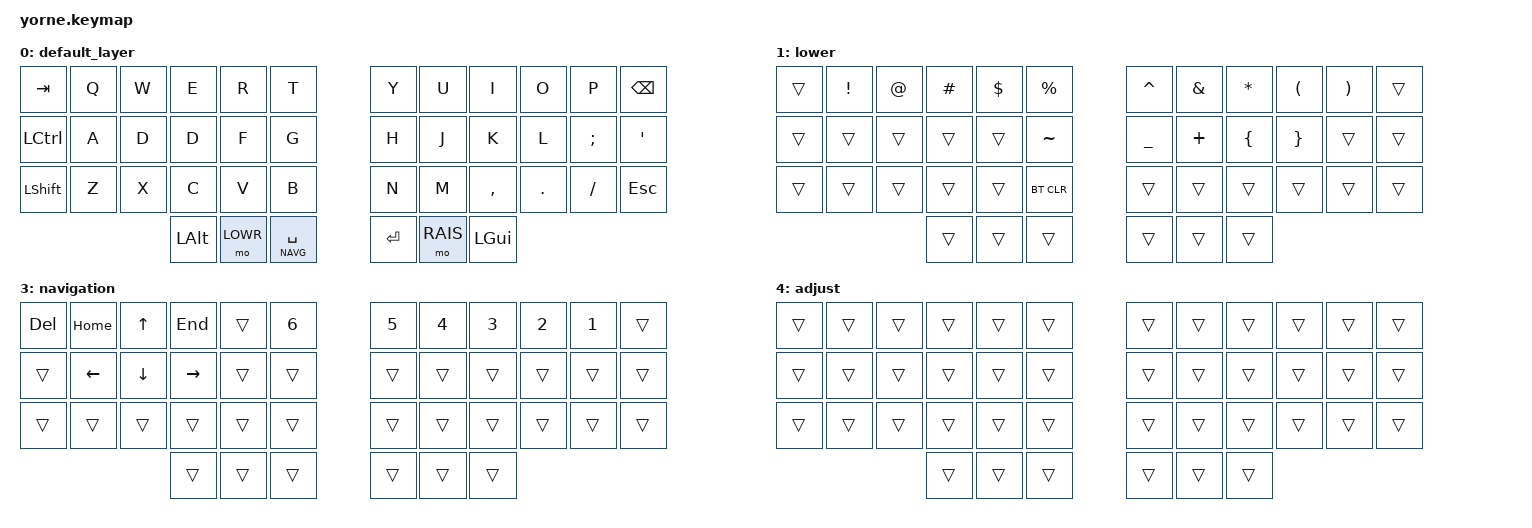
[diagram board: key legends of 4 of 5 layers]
/*
 * Copyright (c) 2024 Ridwan Abdullah
 *
 * SPDX-License-Identifier: MIT
 */

#include <behaviors.dtsi>
#include <dt-bindings/zmk/keys.h>
#include <dt-bindings/zmk/bt.h>
#include <dt-bindings/zmk/outputs.h>

#define LOWR 1
#define RAIS 2
#define NAVG 3
#define ADJT 4

/ {
  // Activate ADJUST layer by pressing raise and lower
  conditional_layers {
        compatible = "zmk,conditional-layers";
        adjust_layer {
            if-layers = <LOWR RAIS>;
            then-layer = <ADJT>;
        };
    };

  keymap {
    compatible = "zmk,keymap";

    default_layer {
      bindings = <
                &kp TAB     &kp Q       &kp W       &kp E       &kp R       &kp T           &kp Y       &kp U       &kp I       &kp O       &kp P       &kp BSPC
                &kp LCTRL   &kp A       &kp D       &kp D       &kp F       &kp G           &kp H       &kp J       &kp K       &kp L       &kp SEMI    &kp SQT
                &kp LSHFT   &kp Z       &kp X       &kp C       &kp V       &kp B           &kp N       &kp M       &kp COMMA   &kp DOT     &kp FSLH    &kp ESC
                                                    &kp LALT    &mo LOWR    &lt NAVG SPACE  &kp ENTER   &mo RAIS    &kp LGUI
      >;
    };

    lower {
      bindings = <
                &trans      &kp EXCL    &kp AT      &kp HASH    &kp DLLR    &kp PRCNT       &kp CARET   &kp AMPS    &kp ASTRK   &kp LPAR    &kp RPAR    &trans
                &trans      &trans      &trans      &trans      &trans      &kp TILDE       &kp UNDER   &kp PLUS    &kp LBRC    &kp RBRC    &trans      &trans
                &trans      &trans      &trans      &trans      &trans      &bt BT_CLR          &trans      &trans      &trans      &trans      &trans      &trans
                                                    &trans      &trans      &trans          &trans      &trans      &trans
      >;
    };
    raise {
      bindings = <
                &trans      &kp N1      &kp N2      &kp N3       &kp N4     &kp N5          &kp N6      &kp N7      &kp N8      &kp N9      &kp N0      &trans
                &trans      &trans      &trans      &trans       &trans     &kp &kp TILDE   &kp MINUS   &kp EQUAL   &kp LBKT    &kp RBKT    &trans      &trans
                &trans      &trans      &trans      &trans       &trans     &bt BT_CLR      &trans      &trans      &trans      &trans      &trans      &trans
                                                    &trans       &trans     &trans          &trans      &trans      &trans
      >;
    };

    navigation {
      bindings = <
                &kp DEL     &kp HOME    &kp UP      &kp END      &trans     &kp N6          &kp N5      &kp N4      &kp N3      &kp N2      &kp N1      &trans
                &trans      &kp LEFT    &kp DOWN    &kp RIGHT    &trans     &trans          &trans      &trans      &trans      &trans      &trans      &trans
                &trans      &trans      &trans      &trans       &trans     &trans          &trans      &trans      &trans      &trans      &trans      &trans
                                                    &trans       &trans     &trans          &trans      &trans      &trans
      >;
    };

    adjust {
      bindings = <
                &trans      &trans      &trans      &trans       &trans     &trans          &trans      &trans      &trans      &trans      &trans      &trans
                &trans      &trans      &trans      &trans       &trans     &trans          &trans      &trans      &trans      &trans      &trans      &trans
                &trans      &trans      &trans      &trans       &trans     &trans          &trans      &trans      &trans      &trans      &trans      &trans
                                                    &trans       &trans     &trans          &trans      &trans      &trans
      >;
    };
  };
};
